VERSION ""

NS_ :

BS_:

BU_: VecTor__XXX

VAL_TABLE_ Cruise_Enable_Enumeration 0 "Disabled" 1 "Cruise Control" 2 "Speed Limit";
VAL_TABLE_ Cruise_State_On_Enumeration 0 "Off" 1 "On";
VAL_TABLE_ Driver_Cruise_Off_Switch_Enumeration 0 "Off" 1 "On";
VAL_TABLE_ Driver_Cruise_On_Switch_Enumeration 0 "Off" 1 "On";
VAL_TABLE_ Driver_Cruise_Limit_On_Switch_Enumeration 0 "Off" 1 "On";
VAL_TABLE_ Driver_Cruise_Cancel_Switch_Enumeration 0 "Off" 1 "On";
VAL_TABLE_ Driver_Cruise_Set_Switch_Enumeration 0 "Off" 1 "On";
VAL_TABLE_ Driver_Cruise_Coast_Switch_Enumeration 0 "Off" 1 "On";
VAL_TABLE_ Driver_Cruise_Resume_Switch_Enumeration 0 "Off" 1 "On";
VAL_TABLE_ Driver_Cruise_Acceleration_Switch_Enumeration 0 "Off" 1 "On";
VAL_TABLE_ Cruise_Exit_Switch_Enumeration 0 "Off" 1 "On";

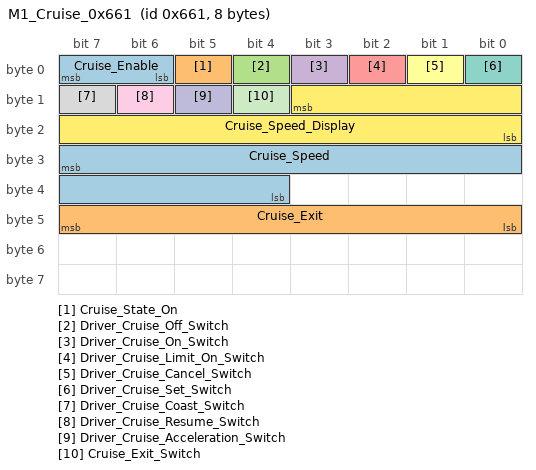
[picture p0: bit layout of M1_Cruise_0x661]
BO_ 1633 M1_Cruise_0x661: 8 Vector__XXX
 SG_ Cruise_Enable : 7|2@0+ (1,0) [0|3] "" Vector__XXX
 SG_ Cruise_State_On : 5|1@0+ (1,0) [0|1] "" Vector__XXX
 SG_ Driver_Cruise_Off_Switch : 4|1@0+ (1,0) [0|1] "" Vector__XXX
 SG_ Driver_Cruise_On_Switch : 3|1@0+ (1,0) [0|1] "" Vector__XXX
 SG_ Driver_Cruise_Limit_On_Switch : 2|1@0+ (1,0) [0|1] "" Vector__XXX
 SG_ Driver_Cruise_Cancel_Switch : 1|1@0+ (1,0) [0|1] "" Vector__XXX
 SG_ Driver_Cruise_Set_Switch : 0|1@0+ (1,0) [0|1] "" Vector__XXX
 SG_ Driver_Cruise_Coast_Switch : 15|1@0+ (1,0) [0|1] "" Vector__XXX
 SG_ Driver_Cruise_Resume_Switch : 14|1@0+ (1,0) [0|1] "" Vector__XXX
 SG_ Driver_Cruise_Acceleration_Switch : 13|1@0+ (1,0) [0|1] "" Vector__XXX
 SG_ Cruise_Exit_Switch : 12|1@0+ (1,0) [0|1] "" Vector__XXX
 SG_ Cruise_Speed_Display : 11|12@0+ (0.1,0) [0|409.5] "km/h" Vector__XXX
 SG_ Cruise_Speed : 31|12@0+ (0.1,0) [0|409.5] "km/h" Vector__XXX
 SG_ Cruise_Exit : 47|8@0- (1,0) [-127|127] "" Vector__XXX
CM_ SG_ 1633 Cruise_Exit "Enumerations are package dependent";

VAL_ 1633 Cruise_Enable 0 "Disabled" 1 "Cruise Control" 2 "Speed Limit";
VAL_ 1633 Cruise_State_On 0 "Off" 1 "On";
VAL_ 1633 Driver_Cruise_Off_Switch 0 "Off" 1 "On";
VAL_ 1633 Driver_Cruise_On_Switch 0 "Off" 1 "On";
VAL_ 1633 Driver_Cruise_Limit_On_Switch 0 "Off" 1 "On";
VAL_ 1633 Driver_Cruise_Cancel_Switch 0 "Off" 1 "On";
VAL_ 1633 Driver_Cruise_Set_Switch 0 "Off" 1 "On";
VAL_ 1633 Driver_Cruise_Coast_Switch 0 "Off" 1 "On";
VAL_ 1633 Driver_Cruise_Resume_Switch 0 "Off" 1 "On";
VAL_ 1633 Driver_Cruise_Acceleration_Switch 0 "Off" 1 "On";
VAL_ 1633 Cruise_Exit_Switch 0 "Off" 1 "On";
